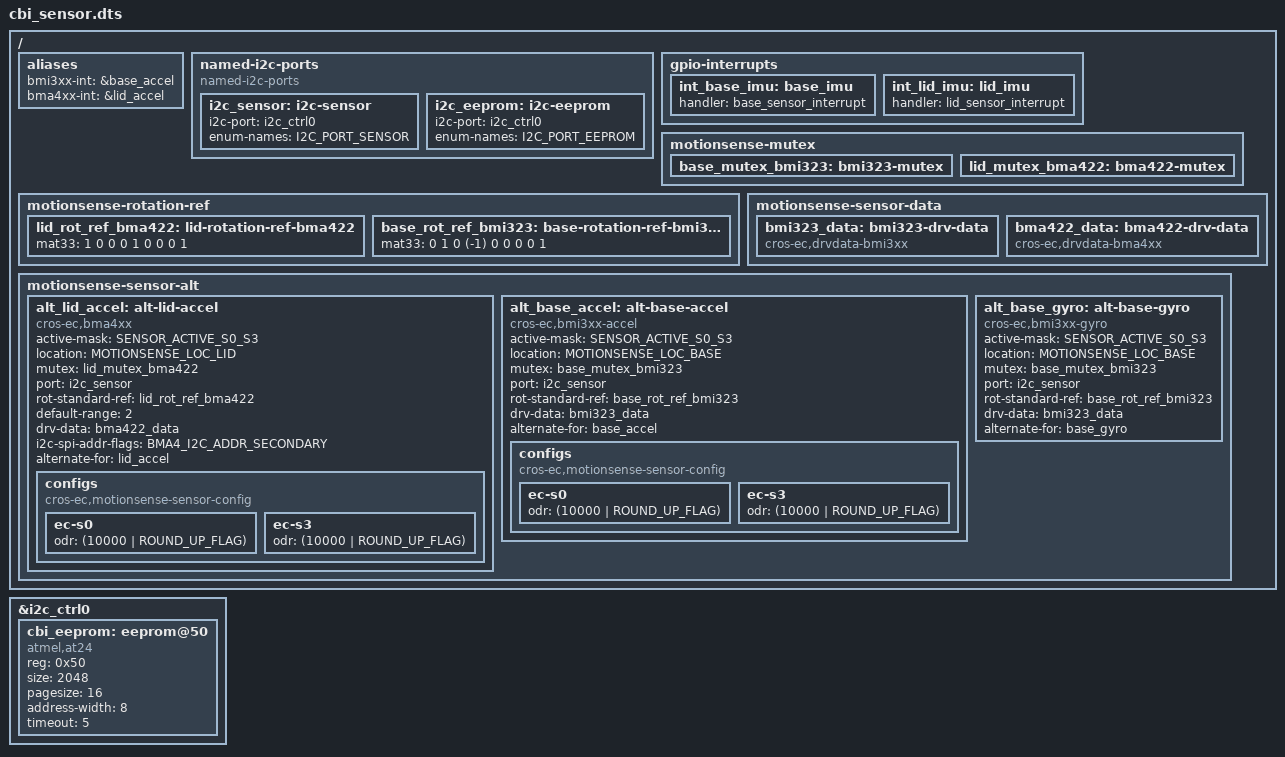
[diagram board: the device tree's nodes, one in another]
/* Copyright 2022 The ChromiumOS Authors
 * Use of this source code is governed by a BSD-style license that can be
 * found in the LICENSE file.
 */


/ {
	aliases {
		/*
		 * motion sense's <>_INT_EVENT is handled
		 * by alias. Using the alias, each driver creates
		 * its own <>_INT_EVENT.
		 */
		bmi3xx-int = &base_accel;
		bma4xx-int = &lid_accel;
	};
	named-i2c-ports {
	    compatible = "named-i2c-ports";

	    i2c_sensor: i2c-sensor {
		    i2c-port = <&i2c_ctrl0>;
		    enum-names = "I2C_PORT_SENSOR";
	    };
	    i2c_eeprom: i2c-eeprom {
		    i2c-port = <&i2c_ctrl0>;
		    enum-names = "I2C_PORT_EEPROM";
	    };
	};
	gpio-interrupts {
		int_base_imu: base_imu {
			handler = "base_sensor_interrupt";
		};

		int_lid_imu: lid_imu {
			handler = "lid_sensor_interrupt";
		};
	};
	motionsense-mutex {
		base_mutex_bmi323: bmi323-mutex {
		};

		lid_mutex_bma422: bma422-mutex {
		};
	};
	/* Rotation matrix used by drivers. */
	motionsense-rotation-ref {
		lid_rot_ref_bma422: lid-rotation-ref-bma422 {
			mat33 = <1 0 0
				 0 1 0
				 0 0 1>;
		};

		base_rot_ref_bmi323: base-rotation-ref-bmi323 {
			mat33 = <0 1 0
				 (-1) 0 0
				 0 0 1>;
		};
	};
	motionsense-sensor-data {
		bmi323_data: bmi323-drv-data {
			compatible = "cros-ec,drvdata-bmi3xx";
			status = "okay";
		};

		bma422_data: bma422-drv-data {
			compatible = "cros-ec,drvdata-bma4xx";
			status = "okay";
		};
	};
	motionsense-sensor-alt {
		alt_lid_accel: alt-lid-accel {
			compatible = "cros-ec,bma4xx";
			status = "okay";

			active-mask = "SENSOR_ACTIVE_S0_S3";
			location = "MOTIONSENSE_LOC_LID";
			mutex = <&lid_mutex_bma422>;
			port = <&i2c_sensor>;
			rot-standard-ref = <&lid_rot_ref_bma422>;
			default-range = <2>;
			drv-data = <&bma422_data>;
			i2c-spi-addr-flags = "BMA4_I2C_ADDR_SECONDARY";
			alternate-for = <&lid_accel>;
			configs {
				compatible =
					"cros-ec,motionsense-sensor-config";
				ec-s0 {
					odr = <(10000 | ROUND_UP_FLAG)>;
				};
				ec-s3 {
					odr = <(10000 | ROUND_UP_FLAG)>;
				};
			};
		};

		alt_base_accel: alt-base-accel {
			compatible = "cros-ec,bmi3xx-accel";
			status = "okay";

			active-mask = "SENSOR_ACTIVE_S0_S3";
			location = "MOTIONSENSE_LOC_BASE";
			mutex = <&base_mutex_bmi323>;
			port = <&i2c_sensor>;
			rot-standard-ref = <&base_rot_ref_bmi323>;
			drv-data = <&bmi323_data>;
			alternate-for = <&base_accel>;
			configs {
				compatible =
					"cros-ec,motionsense-sensor-config";
				ec-s0 {
					odr = <(10000 | ROUND_UP_FLAG)>;
				};
				ec-s3 {
					odr = <(10000 | ROUND_UP_FLAG)>;
				};
			};
		};

		alt_base_gyro: alt-base-gyro {
			compatible = "cros-ec,bmi3xx-gyro";
			status = "okay";

			active-mask = "SENSOR_ACTIVE_S0_S3";
			location = "MOTIONSENSE_LOC_BASE";
			mutex = <&base_mutex_bmi323>;
			port = <&i2c_sensor>;
			rot-standard-ref = <&base_rot_ref_bmi323>;
			drv-data = <&bmi323_data>;
			alternate-for = <&base_gyro>;
		};
	};
};

&i2c_ctrl0 {
	status="okay";

	cbi_eeprom: eeprom@50 {
		compatible = "atmel,at24";
		reg = <0x50>;
		size = <2048>;
		pagesize = <16>;
		address-width = <8>;
		timeout = <5>;
	};
};
